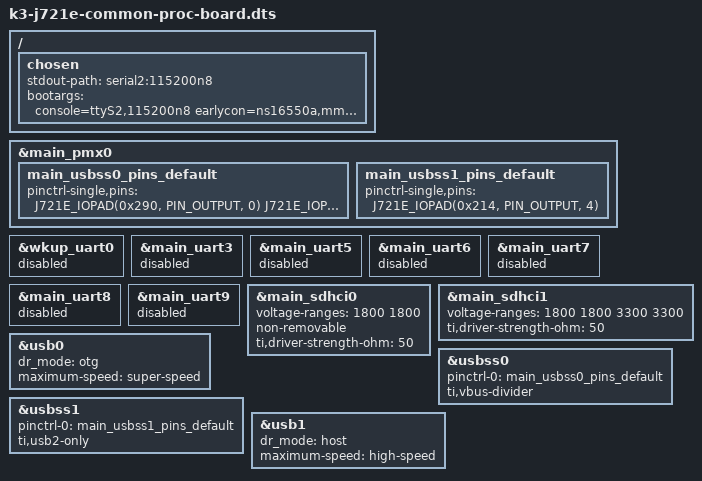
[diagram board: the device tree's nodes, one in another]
// SPDX-License-Identifier: GPL-2.0
/*
 * Copyright (C) 2019 Texas Instruments Incorporated - http://www.ti.com/
 */

/dts-v1/;

#include "k3-j721e-som-p0.dtsi"

/ {
	chosen {
		stdout-path = "serial2:115200n8";
		bootargs = "console=ttyS2,115200n8 earlycon=ns16550a,mmio32,0x02800000";
	};
};

&main_pmx0 {
	main_usbss0_pins_default: main_usbss0_pins_default {
		pinctrl-single,pins = <
			J721E_IOPAD(0x290, PIN_OUTPUT, 0) /* (U6) USB0_DRVVBUS */
			J721E_IOPAD(0x210, PIN_INPUT, 7) /* (W3) MCAN1_RX.GPIO1_3 */
		>;
	};

	main_usbss1_pins_default: main_usbss1_pins_default {
		pinctrl-single,pins = <
			J721E_IOPAD(0x214, PIN_OUTPUT, 4) /* (V4) MCAN1_TX.USB1_DRVVBUS */
		>;
	};
};

&wkup_uart0 {
	/* Wakeup UART is used by System firmware */
	status = "disabled";
};

&main_uart3 {
	/* UART not brought out */
	status = "disabled";
};

&main_uart5 {
	/* UART not brought out */
	status = "disabled";
};

&main_uart6 {
	/* UART not brought out */
	status = "disabled";
};

&main_uart7 {
	/* UART not brought out */
	status = "disabled";
};

&main_uart8 {
	/* UART not brought out */
	status = "disabled";
};

&main_uart9 {
	/* UART not brought out */
	status = "disabled";
};

&main_sdhci0 {
	/* eMMC */
	voltage-ranges = <1800 1800>;
	non-removable;
	ti,driver-strength-ohm = <50>;
};

&main_sdhci1 {
	/* SD/MMC */
	voltage-ranges = <1800 1800 3300 3300>;
	ti,driver-strength-ohm = <50>;
};

&usbss0 {
	pinctrl-names = "default";
	pinctrl-0 = <&main_usbss0_pins_default>;
	ti,vbus-divider;
};

&usb0 {
	dr_mode = "otg";
	maximum-speed = "super-speed";
};

&usbss1 {
	pinctrl-names = "default";
	pinctrl-0 = <&main_usbss1_pins_default>;
	ti,usb2-only;
};

&usb1 {
	dr_mode = "host";
	maximum-speed = "high-speed";
};
